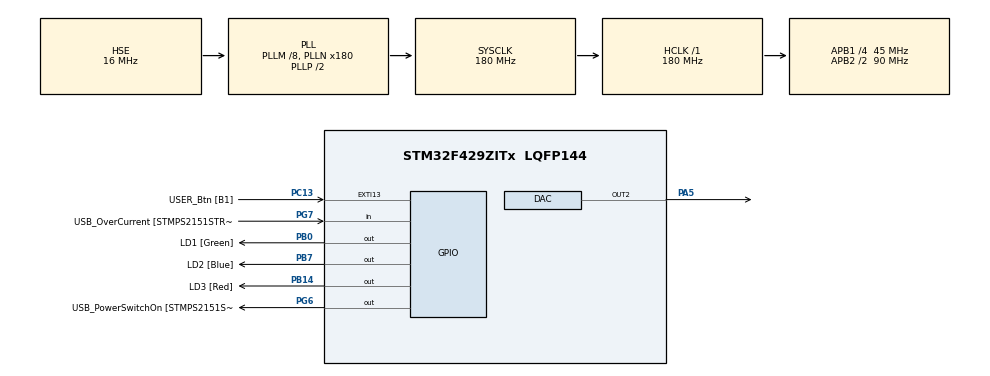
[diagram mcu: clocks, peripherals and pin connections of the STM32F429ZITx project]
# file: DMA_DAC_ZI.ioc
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Mcu.Family=STM32F4
Dma.DAC2.0.MemDataAlignment=DMA_MDATAALIGN_HALFWORD
RCC.CortexFreq_Value=180000000
PG6.Signal=GPIO_Output
PB14.GPIO_Label=LD3 [Red]
PG6.GPIO_Label=USB_PowerSwitchOn [STMPS2151STR_EN]
PA14.GPIO_Label=TCK
RCC.SYSCLKSourceVirtual=RCC_SYSCLKSOURCE_PLLCLK
PB0.GPIO_Label=LD1 [Green]
PC13.GPIO_Label=USER_Btn [B1]
PB13.GPIO_Label=RMII_TXD1 [LAN8742A-CZ-TR_TXD1]
PB13.Signal=ETH_TXD1
PG13.Signal=ETH_TXD0
PG11.Signal=ETH_TX_EN
RCC.SYSCLKSource=RCC_SYSCLKSOURCE_PLLCLK
ProjectManager.StackSize=0x400
SH.COMP_DAC2_group.0=DAC_OUT2,DAC_OUT2
Dma.DAC2.0.PeriphInc=DMA_PINC_DISABLE
VP_TIM7_VS_ClockSourceINT.Mode=Enable_Timer
PA12.Signal=USB_OTG_FS_DP
PH0/OSC_IN.Mode=HSE-External-Oscillator
Dma.DAC2.0.Priority=DMA_PRIORITY_LOW
RCC.HCLKFreq_Value=180000000
RCC.APB2TimFreq_Value=180000000
PH1/OSC_OUT.Signal=RCC_OSC_OUT
TIM7.Period=10-1
PD8.Signal=USART3_TX
Dma.DAC2.0.Direction=DMA_MEMORY_TO_PERIPH
RCC.AHBFreq_Value=180000000
RCC.HSE_VALUE=16000000
RCC.PLLMUL=RCC_PLL_MUL9
DAC.DAC_Trigger2=DAC_TRIGGER_T7_TRGO
PC4.GPIO_Label=RMII_RXD0 [LAN8742A-CZ-TR_RXD0]
PA10.GPIO_Label=USB_ID
PC13.GPIO_PuPd=GPIO_PULLUP
PG7.GPIO_PuPd=GPIO_NOPULL
PB7.Signal=GPIO_Output
PA8.Signal=USB_OTG_FS_SOF
PH1/OSC_OUT.Mode=HSE-External-Oscillator
TIM7.TIM_MasterOutputTrigger=TIM_TRGO_UPDATE
Dma.DAC2.0.MemInc=DMA_MINC_ENABLE
PB7.GPIO_Label=LD2 [Blue]
Mcu.Package=LQFP144
PC14/OSC32_IN.Signal=RCC_OSC32_IN
PA2.GPIO_Label=RMII_MDIO [LAN8742A-CZ-TR_MDIO]
PA10.Signal=USB_OTG_FS_ID
TIM7.AutoReloadPreload=TIM_AUTORELOAD_PRELOAD_DISABLE
RCC.APB2CLKDivider=RCC_HCLK_DIV2
RCC.APB1TimFreq_Value=90000000
PG11.GPIO_Label=RMII_TX_EN [LAN8742A-CZ-TR_TXEN]
PC5.Signal=ETH_RXD1
Dma.Request0=DAC2
NVIC.DMA1_Stream6_IRQn=true\:0\:0\:false\:false\:true\:false\:true
RCC.PLLSourceVirtual=RCC_PLLSOURCE_HSE
PG7.Signal=GPIO_Input
PD9.GPIO_Label=STLK_TX [STM32F103CBT6_PA2]
PC13.Signal=GPXTI13
PA9.GPIO_Label=USB_VBUS
PC4.Signal=ETH_RXD0
PA11.GPIO_Label=USB_DM
PD9.Signal=USART3_RX
RCC.APB1CLKDivider=RCC_HCLK_DIV4
PG13.GPIO_Label=RMII_TXD0 [LAN8742A-CZ-TR_TXD0]
PA12.GPIO_Label=USB_DP
PD8.GPIO_Label=STLK_RX [STM32F103CBT6_PA3]
PA13.Signal=SYS_JTMS-SWDIO
PA8.GPIO_Label=USB_SOF [TP1]
ProjectManager.TargetToolchain=STM32CubeIDE
PA9.Signal=USB_OTG_FS_VBUS
RCC.USBFreq_Value=48000000
RCC.LSE_VALUE=32768
PA1.Signal=ETH_REF_CLK
PB14.Signal=GPIO_Output
PA5.Signal=COMP_DAC2_group
TIM7.Prescaler=1-1
board=NUCLEO-F429ZI
RCC.VCOOutputFreq_Value=360000000
PH0/OSC_IN.Signal=RCC_OSC_IN
RCC.APB2Freq_Value=90000000
RCC.PRESCALERUSB=RCC_USBCLKSOURCE_PLL_DIV1_5
PG7.GPIO_Label=USB_OverCurrent [STMPS2151STR_FAULT]
PA1.GPIO_Label=RMII_REF_CLK [LAN8742A-CZ-TR_REFCLK0]
PC1.GPIO_Label=RMII_MDC [LAN8742A-CZ-TR_MDC]
Dma.DAC2.0.Instance=DMA1_Stream6
Dma.DAC2.0.PeriphDataAlignment=DMA_PDATAALIGN_HALFWORD
Mcu.Name=STM32F429ZITx
PA2.Signal=ETH_MDIO
PA13.GPIO_Label=TMS
RCC.48MHZClocksFreq_Value=90000000
RCC.SYSCLKFreq_VALUE=180000000
PA7.GPIO_Label=RMII_CRS_DV [LAN8742A-CZ-TR_CRS_DV]
Dma.DAC2.0.FIFOMode=DMA_FIFOMODE_DISABLE
PC13.GPIO_ModeDefaultEXTI=GPIO_MODE_IT_RISING
PC5.GPIO_Label=RMII_RXD1 [LAN8742A-CZ-TR_RXD1]
Dma.DAC2.0.Mode=DMA_CIRCULAR
PA11.Signal=USB_OTG_FS_DM
PA14.Signal=SYS_JTCK-SWCLK
ProjectManager.HeapSize=0x200
RCC.HSI_VALUE=16000000
PH0/OSC_IN.GPIO_Label=MCO [STM32F103CBT6_PA8]
NVIC.PriorityGroup=NVIC_PRIORITYGROUP_4
RCC.PLLM=8
RCC.PLLN=180
PC15/OSC32_OUT.Signal=RCC_OSC32_OUT
RCC.APB1Freq_Value=45000000
PB0.Signal=GPIO_Output
PC1.Signal=ETH_MDC
PA7.Signal=ETH_CRS_DV

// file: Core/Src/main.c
/* USER CODE BEGIN Header */
/**
  ******************************************************************************
  * @file           : main.c
  * @brief          : Main program body
  ******************************************************************************
  * @attention
  *
  * <h2><center>&copy; Copyright (c) 2021 STMicroelectronics.
  * All rights reserved.</center></h2>
  *
  * This software component is licensed by ST under BSD 3-Clause license,
  * the "License"; You may not use this file except in compliance with the
  * License. You may obtain a copy of the License at:
  *                        opensource.org/licenses/BSD-3-Clause
  *
  ******************************************************************************
  */
/* USER CODE END Header */
#include "main.h"

/* USER CODE BEGIN Includes */
#include <math.h>

/* USER CODE END Includes */

/* USER CODE BEGIN PD */
#define BUFFER_SIZE 100
/* USER CODE END PD */

DAC_HandleTypeDef hdac;
DMA_HandleTypeDef hdma_dac2;

TIM_HandleTypeDef htim7;

void SystemClock_Config(void);
static void MX_GPIO_Init(void);
static void MX_DMA_Init(void);
static void MX_DAC_Init(void);
static void MX_TIM7_Init(void);

/* USER CODE BEGIN 0 */
uint16_t data[BUFFER_SIZE] = {0};

/* USER CODE END 0 */

int main(void)
{
  /* USER CODE BEGIN 1 */
	for(size_t i = 0;i<BUFFER_SIZE;i++) {
		data[i] = (sin(2*M_PI*i / (BUFFER_SIZE))+1) * (0xFFF)/2;
	}

  /* USER CODE END 1 */

  /* MCU Configuration--------------------------------------------------------*/

  /* Reset of all peripherals, Initializes the Flash interface and the Systick. */
  HAL_Init();

  /* Configure the system clock */
  SystemClock_Config();

  /* Initialize all configured peripherals */
  MX_GPIO_Init();
  MX_DMA_Init();
  MX_DAC_Init();
  MX_TIM7_Init();
  /* USER CODE BEGIN 2 */
  //HAL_TIM_Base_Start(&htim6);
  HAL_TIM_Base_Start(&htim7);
  -//HAL_DAC_Start(&hdac, DAC1_CHANNEL_1);
  HAL_DAC_Start(&hdac, DAC1_CHANNEL_2);
  //HAL_DAC_Start_DMA(&hdac, DAC1_CHANNEL_1, (uint32_t*)data1, BUFFER_SIZE, DAC_ALIGN_12B_R);
  HAL_DAC_Start_DMA(&hdac, DAC1_CHANNEL_2, (uint32_t*)data, BUFFER_SIZE, DAC_ALIGN_12B_R);
  //HAL_DACEx_TriangleWaveGenerate(&hdac, DAC_CHANNEL_1, DAC_TRIANGLEAMPLITUDE_2047);
  //HAL_DAC_Start(&hdac, DAC_CHANNEL_1);

  /* USER CODE END 2 */

  /* Infinite loop */
  while (1)
  {

  }
}

void SystemClock_Config(void)
{
  RCC_OscInitTypeDef RCC_OscInitStruct = {0};
  RCC_ClkInitTypeDef RCC_ClkInitStruct = {0};

  /** Configure the main internal regulator output voltage
  */
  __HAL_RCC_PWR_CLK_ENABLE();
  __HAL_PWR_VOLTAGESCALING_CONFIG(PWR_REGULATOR_VOLTAGE_SCALE1);
  /** Initializes the RCC Oscillators according to the specified parameters
  * in the RCC_OscInitTypeDef structure.
  */
  RCC_OscInitStruct.OscillatorType = RCC_OSCILLATORTYPE_HSE;
  RCC_OscInitStruct.HSEState = RCC_HSE_ON;
  RCC_OscInitStruct.PLL.PLLState = RCC_PLL_ON;
  RCC_OscInitStruct.PLL.PLLSource = RCC_PLLSOURCE_HSE;
  RCC_OscInitStruct.PLL.PLLM = 8;
  RCC_OscInitStruct.PLL.PLLN = 180;
  RCC_OscInitStruct.PLL.PLLP = RCC_PLLP_DIV2;
  RCC_OscInitStruct.PLL.PLLQ = 4;
  if (HAL_RCC_OscConfig(&RCC_OscInitStruct) != HAL_OK)
  {
    Error_Handler();
  }
  /** Activate the Over-Drive mode
  */
  if (HAL_PWREx_EnableOverDrive() != HAL_OK)
  {
    Error_Handler();
  }
  /** Initializes the CPU, AHB and APB buses clocks
  */
  RCC_ClkInitStruct.ClockType = RCC_CLOCKTYPE_HCLK|RCC_CLOCKTYPE_SYSCLK
                              |RCC_CLOCKTYPE_PCLK1|RCC_CLOCKTYPE_PCLK2;
  RCC_ClkInitStruct.SYSCLKSource = RCC_SYSCLKSOURCE_PLLCLK;
  RCC_ClkInitStruct.AHBCLKDivider = RCC_SYSCLK_DIV1;
  RCC_ClkInitStruct.APB1CLKDivider = RCC_HCLK_DIV4;
  RCC_ClkInitStruct.APB2CLKDivider = RCC_HCLK_DIV2;

  if (HAL_RCC_ClockConfig(&RCC_ClkInitStruct, FLASH_LATENCY_5) != HAL_OK)
  {
    Error_Handler();
  }
}

static void MX_DAC_Init(void)
{

  DAC_ChannelConfTypeDef sConfig = {0};

  /** DAC Initialization
  */
  hdac.Instance = DAC;
  if (HAL_DAC_Init(&hdac) != HAL_OK)
  {
    Error_Handler();
  }
  /** DAC channel OUT2 config
  */
  sConfig.DAC_Trigger = DAC_TRIGGER_T7_TRGO;
  sConfig.DAC_OutputBuffer = DAC_OUTPUTBUFFER_ENABLE;
  if (HAL_DAC_ConfigChannel(&hdac, &sConfig, DAC_CHANNEL_2) != HAL_OK)
  {
    Error_Handler();
  }

}

static void MX_TIM7_Init(void)
{

  TIM_MasterConfigTypeDef sMasterConfig = {0};

  htim7.Instance = TIM7;
  htim7.Init.Prescaler = 1-1;
  htim7.Init.CounterMode = TIM_COUNTERMODE_UP;
  htim7.Init.Period = 10-1;
  htim7.Init.AutoReloadPreload = TIM_AUTORELOAD_PRELOAD_DISABLE;
  if (HAL_TIM_Base_Init(&htim7) != HAL_OK)
  {
    Error_Handler();
  }
  sMasterConfig.MasterOutputTrigger = TIM_TRGO_UPDATE;
  sMasterConfig.MasterSlaveMode = TIM_MASTERSLAVEMODE_DISABLE;
  if (HAL_TIMEx_MasterConfigSynchronization(&htim7, &sMasterConfig) != HAL_OK)
  {
    Error_Handler();
  }

}

static void MX_DMA_Init(void)
{

  /* DMA controller clock enable */
  __HAL_RCC_DMA1_CLK_ENABLE();

  /* DMA interrupt init */
  /* DMA1_Stream6_IRQn interrupt configuration */
  HAL_NVIC_SetPriority(DMA1_Stream6_IRQn, 0, 0);
  HAL_NVIC_EnableIRQ(DMA1_Stream6_IRQn);

}

static void MX_GPIO_Init(void)
{
  GPIO_InitTypeDef GPIO_InitStruct = {0};

  /* GPIO Ports Clock Enable */
  __HAL_RCC_GPIOC_CLK_ENABLE();
  __HAL_RCC_GPIOH_CLK_ENABLE();
  __HAL_RCC_GPIOA_CLK_ENABLE();
  __HAL_RCC_GPIOB_CLK_ENABLE();
  __HAL_RCC_GPIOD_CLK_ENABLE();
  __HAL_RCC_GPIOG_CLK_ENABLE();

  /*Configure GPIO pin Output Level */
  HAL_GPIO_WritePin(GPIOB, LD1_Pin|LD3_Pin|LD2_Pin, GPIO_PIN_RESET);

  /*Configure GPIO pin Output Level */
  HAL_GPIO_WritePin(USB_PowerSwitchOn_GPIO_Port, USB_PowerSwitchOn_Pin, GPIO_PIN_RESET);

  /*Configure GPIO pin : USER_Btn_Pin */
  GPIO_InitStruct.Pin = USER_Btn_Pin;
  GPIO_InitStruct.Mode = GPIO_MODE_IT_RISING;
  GPIO_InitStruct.Pull = GPIO_PULLUP;
  HAL_GPIO_Init(USER_Btn_GPIO_Port, &GPIO_InitStruct);

  /*Configure GPIO pins : RMII_MDC_Pin RMII_RXD0_Pin RMII_RXD1_Pin */
  GPIO_InitStruct.Pin = RMII_MDC_Pin|RMII_RXD0_Pin|RMII_RXD1_Pin;
  GPIO_InitStruct.Mode = GPIO_MODE_AF_PP;
  GPIO_InitStruct.Pull = GPIO_NOPULL;
  GPIO_InitStruct.Speed = GPIO_SPEED_FREQ_VERY_HIGH;
  GPIO_InitStruct.Alternate = GPIO_AF11_ETH;
  HAL_GPIO_Init(GPIOC, &GPIO_InitStruct);

  /*Configure GPIO pins : RMII_REF_CLK_Pin RMII_MDIO_Pin RMII_CRS_DV_Pin */
  GPIO_InitStruct.Pin = RMII_REF_CLK_Pin|RMII_MDIO_Pin|RMII_CRS_DV_Pin;
  GPIO_InitStruct.Mode = GPIO_MODE_AF_PP;
  GPIO_InitStruct.Pull = GPIO_NOPULL;
  GPIO_InitStruct.Speed = GPIO_SPEED_FREQ_VERY_HIGH;
  GPIO_InitStruct.Alternate = GPIO_AF11_ETH;
  HAL_GPIO_Init(GPIOA, &GPIO_InitStruct);

  /*Configure GPIO pins : LD1_Pin LD3_Pin LD2_Pin */
  GPIO_InitStruct.Pin = LD1_Pin|LD3_Pin|LD2_Pin;
  GPIO_InitStruct.Mode = GPIO_MODE_OUTPUT_PP;
  GPIO_InitStruct.Pull = GPIO_NOPULL;
  GPIO_InitStruct.Speed = GPIO_SPEED_FREQ_LOW;
  HAL_GPIO_Init(GPIOB, &GPIO_InitStruct);

  /*Configure GPIO pin : RMII_TXD1_Pin */
  GPIO_InitStruct.Pin = RMII_TXD1_Pin;
  GPIO_InitStruct.Mode = GPIO_MODE_AF_PP;
  GPIO_InitStruct.Pull = GPIO_NOPULL;
  GPIO_InitStruct.Speed = GPIO_SPEED_FREQ_VERY_HIGH;
  GPIO_InitStruct.Alternate = GPIO_AF11_ETH;
  HAL_GPIO_Init(RMII_TXD1_GPIO_Port, &GPIO_InitStruct);

  /*Configure GPIO pins : STLK_RX_Pin STLK_TX_Pin */
  GPIO_InitStruct.Pin = STLK_RX_Pin|STLK_TX_Pin;
  GPIO_InitStruct.Mode = GPIO_MODE_AF_PP;
  GPIO_InitStruct.Pull = GPIO_NOPULL;
  GPIO_InitStruct.Speed = GPIO_SPEED_FREQ_VERY_HIGH;
  GPIO_InitStruct.Alternate = GPIO_AF7_USART3;
  HAL_GPIO_Init(GPIOD, &GPIO_InitStruct);

  /*Configure GPIO pin : USB_PowerSwitchOn_Pin */
  GPIO_InitStruct.Pin = USB_PowerSwitchOn_Pin;
  GPIO_InitStruct.Mode = GPIO_MODE_OUTPUT_PP;
  GPIO_InitStruct.Pull = GPIO_NOPULL;
  GPIO_InitStruct.Speed = GPIO_SPEED_FREQ_LOW;
  HAL_GPIO_Init(USB_PowerSwitchOn_GPIO_Port, &GPIO_InitStruct);

  /*Configure GPIO pin : USB_OverCurrent_Pin */
  GPIO_InitStruct.Pin = USB_OverCurrent_Pin;
  GPIO_InitStruct.Mode = GPIO_MODE_INPUT;
  GPIO_InitStruct.Pull = GPIO_NOPULL;
  HAL_GPIO_Init(USB_OverCurrent_GPIO_Port, &GPIO_InitStruct);

  /*Configure GPIO pins : USB_SOF_Pin USB_ID_Pin USB_DM_Pin USB_DP_Pin */
  GPIO_InitStruct.Pin = USB_SOF_Pin|USB_ID_Pin|USB_DM_Pin|USB_DP_Pin;
  GPIO_InitStruct.Mode = GPIO_MODE_AF_PP;
  GPIO_InitStruct.Pull = GPIO_NOPULL;
  GPIO_InitStruct.Speed = GPIO_SPEED_FREQ_VERY_HIGH;
  GPIO_InitStruct.Alternate = GPIO_AF10_OTG_FS;
  HAL_GPIO_Init(GPIOA, &GPIO_InitStruct);

  /*Configure GPIO pin : USB_VBUS_Pin */
  GPIO_InitStruct.Pin = USB_VBUS_Pin;
  GPIO_InitStruct.Mode = GPIO_MODE_INPUT;
  GPIO_InitStruct.Pull = GPIO_NOPULL;
  HAL_GPIO_Init(USB_VBUS_GPIO_Port, &GPIO_InitStruct);

  /*Configure GPIO pins : RMII_TX_EN_Pin RMII_TXD0_Pin */
  GPIO_InitStruct.Pin = RMII_TX_EN_Pin|RMII_TXD0_Pin;
  GPIO_InitStruct.Mode = GPIO_MODE_AF_PP;
  GPIO_InitStruct.Pull = GPIO_NOPULL;
  GPIO_InitStruct.Speed = GPIO_SPEED_FREQ_VERY_HIGH;
  GPIO_InitStruct.Alternate = GPIO_AF11_ETH;
  HAL_GPIO_Init(GPIOG, &GPIO_InitStruct);

}

void Error_Handler(void)
{
  __disable_irq();
  while (1)
  {
  }
}

/************************ (C) COPYRIGHT STMicroelectronics *****END OF FILE****/
